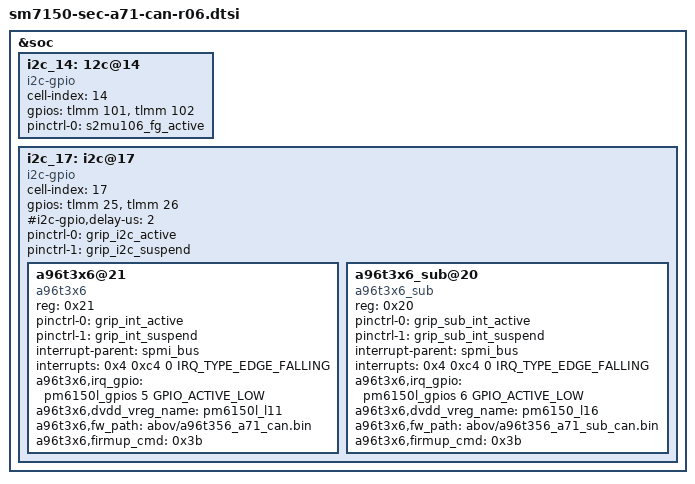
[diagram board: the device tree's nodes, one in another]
/* Copyright (c) 2019, The Linux Foundation. All rights reserved. 

* 

* This program is free software; you can redistribute it and/or modify 

* it under the terms of the GNU General Public License version 2 and 

* only version 2 as published by the Free Software Foundation. 

* 

* This program is distributed in the hope that it will be useful, 

* but WITHOUT ANY WARRANTY; without even the implied warranty of 

* MERCHANTABILITY or FITNESS FOR A PARTICULAR PURPOSE.  See the 

* GNU General Public License for more details. 

*/ 

#include "sm7150-sec-a71-can-r05.dtsi"
#include "sm7150-sec-a71-can-pinctrl-r06.dtsi"
//#include "../drivers/sm7150-camera-sensor-a71-r01.dtsi"

//#include "../drivers/sm7150-sec-a71-display-r01.dtsi"

/delete-node/ &i2c_17;

&soc { 
	i2c_14: 12c@14 {
		status  = "ok";

		cell-index = <14>;
		compatible = "i2c-gpio";
		gpios = <&tlmm 101 0 /*sda*/
			&tlmm 102 0 /*scl*/
			>;

		#address-cells = <1>;
		#size-cells = <0>;
		pinctrl-names = "default";
		pinctrl-0 = <&s2mu106_fg_active>;
	};

	i2c_17: i2c@17 { /* SW I2C */
		status = "ok";

		cell-index = <17>;
		compatible = "i2c-gpio";
		gpios = <&tlmm 25 0 /* sda */
			 &tlmm 26 0 /* scl */
		>;
		#i2c-gpio,delay-us = <2>;
		#address-cells = <1>;
		#size-cells = <0>;
		pinctrl-names = "default", "sleep";
		pinctrl-0 = <&grip_i2c_active>;
		pinctrl-1 = <&grip_i2c_suspend>;

		a96t3x6@21 {
			compatible = "a96t3x6";
			reg = <0x21>;
			pinctrl-names = "default";
			pinctrl-0 = <&grip_int_active>;
			pinctrl-1 = <&grip_int_suspend>;

			interrupt-parent = <&spmi_bus>;
			interrupts = <0x4 0xc4 0 IRQ_TYPE_EDGE_FALLING>;

			a96t3x6,irq_gpio = <&pm6150l_gpios 5 GPIO_ACTIVE_LOW>;
			a96t3x6,dvdd_vreg_name = "pm6150l_l11";
			a96t3x6,fw_path = "abov/a96t356_a71_can.bin";
			a96t3x6,firmup_cmd = <0x3b>;
		};

		a96t3x6_sub@20 {
			compatible = "a96t3x6_sub";
			reg = <0x20>;
			pinctrl-names = "default";
			pinctrl-0 = <&grip_sub_int_active>;
			pinctrl-1 = <&grip_sub_int_suspend>;

			interrupt-parent = <&spmi_bus>;
			interrupts = <0x4 0xc4 0 IRQ_TYPE_EDGE_FALLING>;

			a96t3x6,irq_gpio = <&pm6150l_gpios 6 GPIO_ACTIVE_LOW>;
			a96t3x6,dvdd_vreg_name = "pm6150_l16";
			a96t3x6,fw_path = "abov/a96t356_a71_sub_can.bin";
			a96t3x6,firmup_cmd = <0x3b>;
		};
	};
}; 
